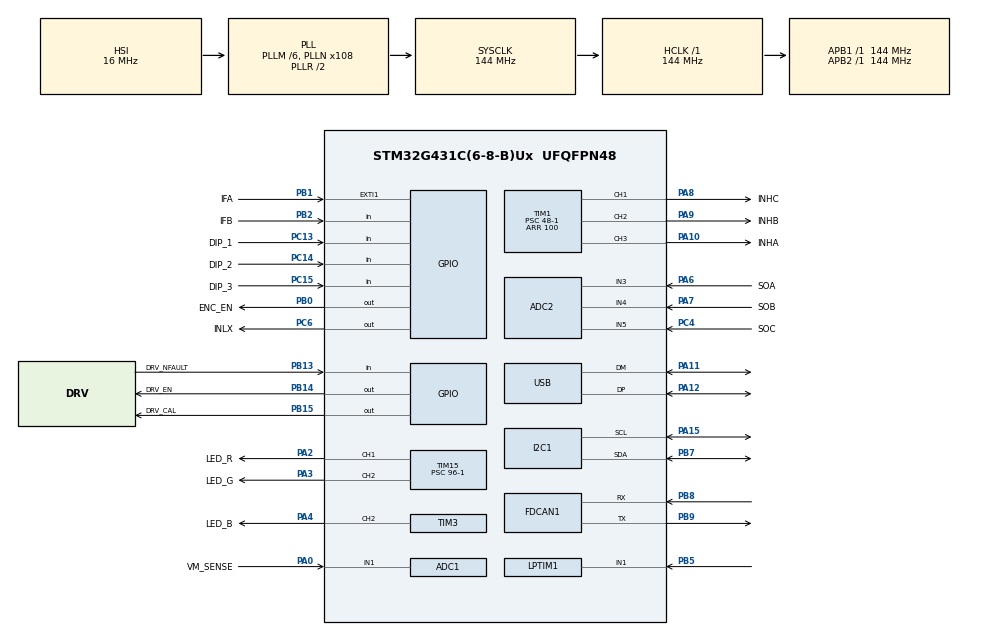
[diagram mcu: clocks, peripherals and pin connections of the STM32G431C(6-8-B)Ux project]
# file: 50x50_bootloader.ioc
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ADC1.Channel-1\#ChannelRegularConversion=ADC_CHANNEL_1
ADC1.Channel-2\#ChannelRegularConversion=ADC_CHANNEL_TEMPSENSOR_ADC1
ADC1.ClockPrescaler=ADC_CLOCK_ASYNC_DIV128
ADC1.ContinuousConvMode=ENABLE
ADC1.DMAContinuousRequests=ENABLE
ADC1.NbrOfConversion=2
ADC1.NbrOfConversionFlag=1
ADC1.OffsetNumber-1\#ChannelRegularConversion=ADC_OFFSET_NONE
ADC1.OffsetNumber-2\#ChannelRegularConversion=ADC_OFFSET_NONE
ADC1.Rank-1\#ChannelRegularConversion=1
ADC1.Rank-2\#ChannelRegularConversion=2
ADC1.SamplingTime-1\#ChannelRegularConversion=ADC_SAMPLETIME_2CYCLES_5
ADC1.SamplingTime-2\#ChannelRegularConversion=ADC_SAMPLETIME_247CYCLES_5
ADC1.master=1
ADC2.Channel-2\#ChannelRegularConversion=ADC_CHANNEL_3
ADC2.Channel-3\#ChannelRegularConversion=ADC_CHANNEL_4
ADC2.Channel-4\#ChannelRegularConversion=ADC_CHANNEL_5
ADC2.ClockPrescaler=ADC_CLOCK_ASYNC_DIV128
ADC2.ContinuousConvMode=ENABLE
ADC2.DMAContinuousRequests=DISABLE
ADC2.EOCSelection=ADC_EOC_SEQ_CONV
ADC2.ExternalTrigConv=ADC_EXTERNALTRIG_T1_TRGO
ADC2.NbrOfConversion=3
ADC2.NbrOfConversionFlag=1
ADC2.OffsetNumber-2\#ChannelRegularConversion=ADC_OFFSET_NONE
ADC2.OffsetNumber-3\#ChannelRegularConversion=ADC_OFFSET_NONE
ADC2.OffsetNumber-4\#ChannelRegularConversion=ADC_OFFSET_NONE
ADC2.Overrun=ADC_OVR_DATA_PRESERVED
ADC2.Rank-2\#ChannelRegularConversion=1
ADC2.Rank-3\#ChannelRegularConversion=2
ADC2.Rank-4\#ChannelRegularConversion=3
ADC2.SamplingTime-2\#ChannelRegularConversion=ADC_SAMPLETIME_6CYCLES_5
ADC2.SamplingTime-3\#ChannelRegularConversion=ADC_SAMPLETIME_6CYCLES_5
ADC2.SamplingTime-4\#ChannelRegularConversion=ADC_SAMPLETIME_6CYCLES_5
Dma.ADC1.0.Direction=DMA_PERIPH_TO_MEMORY
Dma.ADC1.0.EventEnable=DISABLE
Dma.ADC1.0.Instance=DMA1_Channel1
Dma.ADC1.0.MemDataAlignment=DMA_MDATAALIGN_WORD
Dma.ADC1.0.MemInc=DMA_MINC_ENABLE
Dma.ADC1.0.Mode=DMA_CIRCULAR
Dma.ADC1.0.PeriphDataAlignment=DMA_PDATAALIGN_WORD
Dma.ADC1.0.PeriphInc=DMA_PINC_DISABLE
Dma.ADC1.0.Polarity=HAL_DMAMUX_REQ_GEN_RISING
Dma.ADC1.0.Priority=DMA_PRIORITY_LOW
Dma.ADC1.0.RequestNumber=1
Dma.ADC1.0.SignalID=NONE
Dma.ADC1.0.SyncEnable=DISABLE
Dma.ADC1.0.SyncPolarity=HAL_DMAMUX_SYNC_NO_EVENT
Dma.ADC1.0.SyncRequestNumber=1
Dma.ADC1.0.SyncSignalID=NONE
Dma.ADC2.1.Direction=DMA_PERIPH_TO_MEMORY
Dma.ADC2.1.EventEnable=DISABLE
Dma.ADC2.1.Instance=DMA1_Channel2
Dma.ADC2.1.MemDataAlignment=DMA_MDATAALIGN_WORD
Dma.ADC2.1.MemInc=DMA_MINC_ENABLE
Dma.ADC2.1.Mode=DMA_CIRCULAR
Dma.ADC2.1.PeriphDataAlignment=DMA_PDATAALIGN_WORD
Dma.ADC2.1.PeriphInc=DMA_PINC_DISABLE
Dma.ADC2.1.Polarity=HAL_DMAMUX_REQ_GEN_RISING
Dma.ADC2.1.Priority=DMA_PRIORITY_MEDIUM
Dma.ADC2.1.RequestNumber=1
Dma.ADC2.1.SignalID=NONE
Dma.ADC2.1.SyncEnable=DISABLE
Dma.ADC2.1.SyncPolarity=HAL_DMAMUX_SYNC_NO_EVENT
Dma.ADC2.1.SyncRequestNumber=1
Dma.ADC2.1.SyncSignalID=NONE
Dma.Request0=ADC1
Dma.Request1=ADC2
FDCAN1.AutoRetransmission=DISABLE
FDCAN1.CalculateBaudRateNominal=500000
FDCAN1.CalculateTimeBitNominal=2000
FDCAN1.CalculateTimeQuantumNominal=111.11111111111111
FDCAN1.NominalTimeSeg1=15
FDCAN1.TransmitPause=ENABLE
FREERTOS.Tasks01=defaultTask,24,128,StartDefaultTask,Default,NULL,Dynamic,NULL,NULL;statusBlink,8,128,StartStatusBlink,Default,NULL,Dynamic,NULL,NULL;mainStateLoop,40,128,StartMainStateLoop,Default,NULL,Dynamic,NULL,NULL
I2C1.Timing=0x20B0D9FF
Mcu.Family=STM32G4
Mcu.Name=STM32G431C(6-8-B)Ux
Mcu.Package=UFQFPN48
NVIC.DMA1_Channel1_IRQn=true\:5\:0\:false\:false\:true\:true\:false\:true\:true
NVIC.DMA1_Channel2_IRQn=true\:5\:0\:false\:false\:true\:true\:false\:true\:true
NVIC.EXTI1_IRQn=true\:4\:0\:true\:false\:true\:false\:true\:true\:true
NVIC.FDCAN1_IT0_IRQn=true\:5\:0\:false\:false\:true\:true\:true\:true\:true
NVIC.PriorityGroup=NVIC_PRIORITYGROUP_4
NVIC.TIM2_IRQn=true\:15\:0\:false\:false\:true\:false\:false\:true\:true
NVIC.TIM6_DAC_IRQn=true\:5\:0\:true\:false\:true\:true\:true\:true\:true
NVIC.TimeBase=TIM2_IRQn
NVIC.TimeBaseIP=TIM2
NVIC.USB_LP_IRQn=true\:5\:0\:false\:false\:true\:true\:false\:true\:true
PA0.GPIO_Label=VM_SENSE
PA0.Mode=IN1-Single-Ended
PA0.Signal=ADC1_IN1
PA10.GPIO_Label=INHA
PA10.Signal=S_TIM1_CH3
PA11.Mode=Device
PA11.Signal=USB_DM
PA12.Mode=Device
PA12.Signal=USB_DP
PA13.Mode=Trace_Asynchronous_SW
PA13.Signal=SYS_JTMS-SWDIO
PA14.Mode=Trace_Asynchronous_SW
PA14.Signal=SYS_JTCK-SWCLK
PA15.Mode=I2C
PA15.Signal=I2C1_SCL
PA2.GPIO_Label=LED_R
PA2.Signal=S_TIM15_CH1
PA3.GPIO_Label=LED_G
PA3.Signal=S_TIM15_CH2
PA4.GPIO_Label=LED_B
PA4.Signal=S_TIM3_CH2
PA6.GPIO_Label=SOA
PA6.Mode=IN3-Single-Ended
PA6.Signal=ADC2_IN3
PA7.GPIO_Label=SOB
PA7.Mode=IN4-Single-Ended
PA7.Signal=ADC2_IN4
PA8.GPIO_Label=INHC
PA8.Signal=S_TIM1_CH1
PA9.GPIO_Label=INHB
PA9.Signal=S_TIM1_CH2
PB0.GPIO_Label=ENC_EN
PB0.Signal=GPIO_Output
PB1.GPIO_Label=IFA
PB1.Signal=GPXTI1
PB13.GPIO_Label=DRV_NFAULT
PB13.Signal=GPIO_Input
PB14.GPIO_Label=DRV_EN
PB14.Signal=GPIO_Output
PB15.GPIO_Label=DRV_CAL
PB15.Signal=GPIO_Output
PB2.GPIO_Label=IFB
PB2.Signal=GPIO_Input
PB3.Mode=Trace_Asynchronous_SW
PB3.Signal=SYS_JTDO-SWO
PB5.Mode=Counts_external_clock_standalone_1X_occur1
PB5.Signal=LPTIM1_IN1
PB7.Mode=I2C
PB7.Signal=I2C1_SDA
PB8-BOOT0.Mode=FDCAN_Activate
PB8-BOOT0.Signal=FDCAN1_RX
PB9.Mode=FDCAN_Activate
PB9.Signal=FDCAN1_TX
PC13.GPIO_Label=DIP_1
PC13.Signal=GPIO_Input
PC14-OSC32_IN.GPIO_Label=DIP_2
PC14-OSC32_IN.Signal=GPIO_Input
PC15-OSC32_OUT.GPIO_Label=DIP_3
PC15-OSC32_OUT.Signal=GPIO_Input
PC4.GPIO_Label=SOC
PC4.Mode=IN5-Single-Ended
PC4.Signal=ADC2_IN5
PC6.GPIO_Label=INLX
PC6.Signal=GPIO_Output
ProjectManager.HeapSize=0x200
ProjectManager.StackSize=0x400
ProjectManager.TargetToolchain=Makefile
RCC.ADC12Freq_Value=144000000
RCC.AHBFreq_Value=144000000
RCC.APB1Freq_Value=144000000
RCC.APB1TimFreq_Value=144000000
RCC.APB2Freq_Value=144000000
RCC.APB2TimFreq_Value=144000000
RCC.CortexFreq_Value=144000000
RCC.EXTERNAL_CLOCK_VALUE=12288000
RCC.HCLKFreq_Value=144000000
RCC.HSE_VALUE=8000000
RCC.HSI48_VALUE=48000000
RCC.HSI_VALUE=16000000
RCC.LSE_VALUE=32768
RCC.PLLM=RCC_PLLM_DIV6
RCC.PLLN=108
RCC.PLLQ=RCC_PLLQ_DIV6
RCC.SYSCLKFreq_VALUE=144000000
RCC.SYSCLKSource=RCC_SYSCLKSOURCE_PLLCLK
RCC.USBFreq_Value=48000000
RCC.VCOOutputFreq_Value=288000000
SH.S_TIM15_CH1.0=TIM15_CH1,PWM Generation1 CH1
SH.S_TIM15_CH2.0=TIM15_CH2,PWM Generation2 CH2
SH.S_TIM1_CH1.0=TIM1_CH1,PWM Generation1 CH1
SH.S_TIM1_CH2.0=TIM1_CH2,PWM Generation2 CH2
SH.S_TIM1_CH3.0=TIM1_CH3,PWM Generation3 CH3
SH.S_TIM3_CH2.0=TIM3_CH2,PWM Generation2 CH2
TIM1.Channel-PWM\ Generation1\ CH1=TIM_CHANNEL_1
TIM1.Channel-PWM\ Generation2\ CH2=TIM_CHANNEL_2
TIM1.Channel-PWM\ Generation3\ CH3=TIM_CHANNEL_3
TIM1.CounterMode=TIM_COUNTERMODE_CENTERALIGNED1
TIM1.PeriodNoDither=100
TIM1.Prescaler=48-1
TIM1.TIM_MasterOutputTrigger=TIM_TRGO_UPDATE
TIM15.Channel-PWM\ Generation1\ CH1=TIM_CHANNEL_1
TIM15.Channel-PWM\ Generation2\ CH2=TIM_CHANNEL_2
TIM15.OCIdleState_1=TIM_OCIDLESTATE_SET
TIM15.OCIdleState_2=TIM_OCIDLESTATE_SET
TIM15.OCPolarity_1=TIM_OCPOLARITY_LOW
TIM15.OCPolarity_2=TIM_OCPOLARITY_LOW
TIM15.PeriodNoDither=200-1
TIM15.Prescaler=96-1
TIM3.Channel-PWM\ Generation2\ CH2=TIM_CHANNEL_2
TIM3.OCPolarity_2=TIM_OCPOLARITY_LOW
TIM3.PeriodNoDither=200-1
TIM3.Prescaler=96 -1
TIM6.PeriodNoDither=100-1
TIM6.Prescaler=144-1
TIM7.Prescaler=14400-1
USB.Sof_enable=ENABLE
USB_DEVICE.CLASS_NAME_FS=CDC
USB_DEVICE.PRODUCT_STRING_CDC_FS=50x50-Drive
USB_DEVICE.USBD_DEBUG_LEVEL=1
USB_DEVICE.USBD_SELF_POWERED=0
USB_DEVICE.VirtualMode=Cdc
USB_DEVICE.VirtualModeFS=Cdc_FS
VP_ADC1_TempSens_Input.Mode=IN-TempSens
VP_FREERTOS_VS_CMSIS_V2.Mode=CMSIS_V2
VP_SYS_VS_DBSignals.Mode=DisableDeadBatterySignals
VP_SYS_VS_tim2.Mode=TIM2
VP_TIM1_VS_ClockSourceINT.Mode=Internal
VP_TIM6_VS_ClockSourceINT.Mode=Enable_Timer
VP_TIM7_VS_ClockSourceINT.Mode=Enable_Timer
VP_USB_DEVICE_VS_USB_DEVICE_CDC_FS.Mode=CDC_FS
board=custom

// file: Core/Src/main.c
/* USER CODE BEGIN Header */
/**
  ******************************************************************************
  * @file           : main.c
  * @brief          : Main program body
  ******************************************************************************
  * @attention
  *
  * Copyright (c) 2023 STMicroelectronics.
  * All rights reserved.
  *
  * This software is licensed under terms that can be found in the LICENSE file
  * in the root directory of this software component.
  * If no LICENSE file comes with this software, it is provided AS-IS.
  *
  ******************************************************************************
  */
/* USER CODE END Header */
#include "main.h"
#include "cmsis_os.h"
#include "usb_device.h"

/* USER CODE BEGIN Includes */
#include "bootloader.h"
/* USER CODE END Includes */

ADC_HandleTypeDef hadc1;
ADC_HandleTypeDef hadc2;
DMA_HandleTypeDef hdma_adc1;
DMA_HandleTypeDef hdma_adc2;

FDCAN_HandleTypeDef hfdcan1;

I2C_HandleTypeDef hi2c1;

LPTIM_HandleTypeDef hlptim1;

TIM_HandleTypeDef htim1;
TIM_HandleTypeDef htim3;
TIM_HandleTypeDef htim6;
TIM_HandleTypeDef htim7;
TIM_HandleTypeDef htim15;

/* Definitions for defaultTask */
osThreadId_t defaultTaskHandle;
const osThreadAttr_t defaultTask_attributes = {
  .name = "defaultTask",
  .priority = (osPriority_t) osPriorityNormal,
  .stack_size = 128 * 4
};
/* Definitions for statusBlink */
osThreadId_t statusBlinkHandle;
const osThreadAttr_t statusBlink_attributes = {
  .name = "statusBlink",
  .priority = (osPriority_t) osPriorityLow,
  .stack_size = 128 * 4
};
/* Definitions for mainStateLoop */
osThreadId_t mainStateLoopHandle;
const osThreadAttr_t mainStateLoop_attributes = {
  .name = "mainStateLoop",
  .priority = (osPriority_t) osPriorityHigh,
  .stack_size = 128 * 4
};

void SystemClock_Config(void);
static void MX_GPIO_Init(void);
static void MX_DMA_Init(void);
static void MX_FDCAN1_Init(void);
static void MX_ADC1_Init(void);
static void MX_ADC2_Init(void);
static void MX_TIM1_Init(void);
static void MX_I2C1_Init(void);
static void MX_TIM3_Init(void);
static void MX_TIM15_Init(void);
static void MX_TIM6_Init(void);
static void MX_LPTIM1_Init(void);
static void MX_TIM7_Init(void);
void StartDefaultTask(void *argument);
void StartStatusBlink(void *argument);
void StartMainStateLoop(void *argument);

int main(void)
{
  /* USER CODE BEGIN 1 */
  // Hello world 2
  /* USER CODE END 1 */

  /* MCU Configuration--------------------------------------------------------*/

  /* Reset of all peripherals, Initializes the Flash interface and the Systick. */
  HAL_Init();

  /* Configure the system clock */
  SystemClock_Config();

  /* Initialize all configured peripherals */
  MX_GPIO_Init();
  MX_DMA_Init();
  MX_FDCAN1_Init();
  MX_ADC1_Init();
  MX_ADC2_Init();
  MX_TIM1_Init();
  MX_I2C1_Init();
  MX_USB_Device_Init();
  MX_TIM3_Init();
  MX_TIM15_Init();
  MX_TIM6_Init();
  MX_LPTIM1_Init();
  MX_TIM7_Init();
  /* USER CODE BEGIN 2 */
  bootloader_init();

  HAL_GPIO_WritePin(LED_R_GPIO_Port, LED_R_Pin, 1);
  HAL_GPIO_WritePin(LED_G_GPIO_Port, LED_G_Pin, 1);
  HAL_GPIO_WritePin(LED_B_GPIO_Port, LED_B_Pin, 1);
  /* USER CODE END 2 */

  /* Init scheduler */
  osKernelInitialize();

  /* Create the thread(s) */
  /* creation of defaultTask */
  defaultTaskHandle = osThreadNew(StartDefaultTask, NULL, &defaultTask_attributes);

  /* creation of statusBlink */
  statusBlinkHandle = osThreadNew(StartStatusBlink, NULL, &statusBlink_attributes);

  /* creation of mainStateLoop */
  mainStateLoopHandle = osThreadNew(StartMainStateLoop, NULL, &mainStateLoop_attributes);

  /* Start scheduler */
  osKernelStart();

  /* We should never get here as control is now taken by the scheduler */
  /* Infinite loop */
  while (1)
  {

    /* USER CODE BEGIN 3 */
    bootloader_loop();
  }
  /* USER CODE END 3 */
}

void SystemClock_Config(void)
{
  RCC_OscInitTypeDef RCC_OscInitStruct = {0};
  RCC_ClkInitTypeDef RCC_ClkInitStruct = {0};

  /** Configure the main internal regulator output voltage
  */
  HAL_PWREx_ControlVoltageScaling(PWR_REGULATOR_VOLTAGE_SCALE1);

  /** Initializes the RCC Oscillators according to the specified parameters
  * in the RCC_OscInitTypeDef structure.
  */
  RCC_OscInitStruct.OscillatorType = RCC_OSCILLATORTYPE_HSI;
  RCC_OscInitStruct.HSIState = RCC_HSI_ON;
  RCC_OscInitStruct.HSICalibrationValue = RCC_HSICALIBRATION_DEFAULT;
  RCC_OscInitStruct.PLL.PLLState = RCC_PLL_ON;
  RCC_OscInitStruct.PLL.PLLSource = RCC_PLLSOURCE_HSI;
  RCC_OscInitStruct.PLL.PLLM = RCC_PLLM_DIV6;
  RCC_OscInitStruct.PLL.PLLN = 108;
  RCC_OscInitStruct.PLL.PLLP = RCC_PLLP_DIV2;
  RCC_OscInitStruct.PLL.PLLQ = RCC_PLLQ_DIV6;
  RCC_OscInitStruct.PLL.PLLR = RCC_PLLR_DIV2;
  if (HAL_RCC_OscConfig(&RCC_OscInitStruct) != HAL_OK)
  {
    Error_Handler();
  }

  /** Initializes the CPU, AHB and APB buses clocks
  */
  RCC_ClkInitStruct.ClockType = RCC_CLOCKTYPE_HCLK|RCC_CLOCKTYPE_SYSCLK
                              |RCC_CLOCKTYPE_PCLK1|RCC_CLOCKTYPE_PCLK2;
  RCC_ClkInitStruct.SYSCLKSource = RCC_SYSCLKSOURCE_PLLCLK;
  RCC_ClkInitStruct.AHBCLKDivider = RCC_SYSCLK_DIV1;
  RCC_ClkInitStruct.APB1CLKDivider = RCC_HCLK_DIV1;
  RCC_ClkInitStruct.APB2CLKDivider = RCC_HCLK_DIV1;

  if (HAL_RCC_ClockConfig(&RCC_ClkInitStruct, FLASH_LATENCY_4) != HAL_OK)
  {
    Error_Handler();
  }
}

static void MX_ADC1_Init(void)
{

  ADC_MultiModeTypeDef multimode = {0};
  ADC_ChannelConfTypeDef sConfig = {0};

  /** Common config
  */
  hadc1.Instance = ADC1;
  hadc1.Init.ClockPrescaler = ADC_CLOCK_ASYNC_DIV128;
  hadc1.Init.Resolution = ADC_RESOLUTION_12B;
  hadc1.Init.DataAlign = ADC_DATAALIGN_RIGHT;
  hadc1.Init.GainCompensation = 0;
  hadc1.Init.ScanConvMode = ADC_SCAN_ENABLE;
  hadc1.Init.EOCSelection = ADC_EOC_SINGLE_CONV;
  hadc1.Init.LowPowerAutoWait = DISABLE;
  hadc1.Init.ContinuousConvMode = ENABLE;
  hadc1.Init.NbrOfConversion = 2;
  hadc1.Init.DiscontinuousConvMode = DISABLE;
  hadc1.Init.ExternalTrigConv = ADC_SOFTWARE_START;
  hadc1.Init.ExternalTrigConvEdge = ADC_EXTERNALTRIGCONVEDGE_NONE;
  hadc1.Init.DMAContinuousRequests = ENABLE;
  hadc1.Init.Overrun = ADC_OVR_DATA_PRESERVED;
  hadc1.Init.OversamplingMode = DISABLE;
  if (HAL_ADC_Init(&hadc1) != HAL_OK)
  {
    Error_Handler();
  }

  /** Configure the ADC multi-mode
  */
  multimode.Mode = ADC_MODE_INDEPENDENT;
  if (HAL_ADCEx_MultiModeConfigChannel(&hadc1, &multimode) != HAL_OK)
  {
    Error_Handler();
  }

  /** Configure Regular Channel
  */
  sConfig.Channel = ADC_CHANNEL_1;
  sConfig.Rank = ADC_REGULAR_RANK_1;
  sConfig.SamplingTime = ADC_SAMPLETIME_2CYCLES_5;
  sConfig.SingleDiff = ADC_SINGLE_ENDED;
  sConfig.OffsetNumber = ADC_OFFSET_NONE;
  sConfig.Offset = 0;
  if (HAL_ADC_ConfigChannel(&hadc1, &sConfig) != HAL_OK)
  {
    Error_Handler();
  }

  /** Configure Regular Channel
  */
  sConfig.Channel = ADC_CHANNEL_TEMPSENSOR_ADC1;
  sConfig.Rank = ADC_REGULAR_RANK_2;
  sConfig.SamplingTime = ADC_SAMPLETIME_247CYCLES_5;
  if (HAL_ADC_ConfigChannel(&hadc1, &sConfig) != HAL_OK)
  {
    Error_Handler();
  }

}

static void MX_ADC2_Init(void)
{

  ADC_ChannelConfTypeDef sConfig = {0};

  /** Common config
  */
  hadc2.Instance = ADC2;
  hadc2.Init.ClockPrescaler = ADC_CLOCK_ASYNC_DIV128;
  hadc2.Init.Resolution = ADC_RESOLUTION_12B;
  hadc2.Init.DataAlign = ADC_DATAALIGN_RIGHT;
  hadc2.Init.GainCompensation = 0;
  hadc2.Init.ScanConvMode = ADC_SCAN_ENABLE;
  hadc2.Init.EOCSelection = ADC_EOC_SEQ_CONV;
  hadc2.Init.LowPowerAutoWait = DISABLE;
  hadc2.Init.ContinuousConvMode = ENABLE;
  hadc2.Init.NbrOfConversion = 3;
  hadc2.Init.DiscontinuousConvMode = DISABLE;
  hadc2.Init.ExternalTrigConv = ADC_EXTERNALTRIG_T1_TRGO;
  hadc2.Init.ExternalTrigConvEdge = ADC_EXTERNALTRIGCONVEDGE_RISING;
  hadc2.Init.DMAContinuousRequests = DISABLE;
  hadc2.Init.Overrun = ADC_OVR_DATA_PRESERVED;
  hadc2.Init.OversamplingMode = DISABLE;
  if (HAL_ADC_Init(&hadc2) != HAL_OK)
  {
    Error_Handler();
  }

  /** Configure Regular Channel
  */
  sConfig.Channel = ADC_CHANNEL_3;
  sConfig.Rank = ADC_REGULAR_RANK_1;
  sConfig.SamplingTime = ADC_SAMPLETIME_6CYCLES_5;
  sConfig.SingleDiff = ADC_SINGLE_ENDED;
  sConfig.OffsetNumber = ADC_OFFSET_NONE;
  sConfig.Offset = 0;
  if (HAL_ADC_ConfigChannel(&hadc2, &sConfig) != HAL_OK)
  {
    Error_Handler();
  }

  /** Configure Regular Channel
  */
  sConfig.Channel = ADC_CHANNEL_4;
  sConfig.Rank = ADC_REGULAR_RANK_2;
  if (HAL_ADC_ConfigChannel(&hadc2, &sConfig) != HAL_OK)
  {
    Error_Handler();
  }

  /** Configure Regular Channel
  */
  sConfig.Channel = ADC_CHANNEL_5;
  sConfig.Rank = ADC_REGULAR_RANK_3;
  if (HAL_ADC_ConfigChannel(&hadc2, &sConfig) != HAL_OK)
  {
    Error_Handler();
  }

}

static void MX_FDCAN1_Init(void)
{

  hfdcan1.Instance = FDCAN1;
  hfdcan1.Init.ClockDivider = FDCAN_CLOCK_DIV1;
  hfdcan1.Init.FrameFormat = FDCAN_FRAME_CLASSIC;
  hfdcan1.Init.Mode = FDCAN_MODE_NORMAL;
  hfdcan1.Init.AutoRetransmission = DISABLE;
  hfdcan1.Init.TransmitPause = ENABLE;
  hfdcan1.Init.ProtocolException = DISABLE;
  hfdcan1.Init.NominalPrescaler = 16;
  hfdcan1.Init.NominalSyncJumpWidth = 1;
  hfdcan1.Init.NominalTimeSeg1 = 15;
  hfdcan1.Init.NominalTimeSeg2 = 2;
  hfdcan1.Init.DataPrescaler = 1;
  hfdcan1.Init.DataSyncJumpWidth = 1;
  hfdcan1.Init.DataTimeSeg1 = 1;
  hfdcan1.Init.DataTimeSeg2 = 1;
  hfdcan1.Init.StdFiltersNbr = 0;
  hfdcan1.Init.ExtFiltersNbr = 0;
  hfdcan1.Init.TxFifoQueueMode = FDCAN_TX_FIFO_OPERATION;
  if (HAL_FDCAN_Init(&hfdcan1) != HAL_OK)
  {
    Error_Handler();
  }

}

static void MX_I2C1_Init(void)
{

  hi2c1.Instance = I2C1;
  hi2c1.Init.Timing = 0x20B0D9FF;
  hi2c1.Init.OwnAddress1 = 0;
  hi2c1.Init.AddressingMode = I2C_ADDRESSINGMODE_7BIT;
  hi2c1.Init.DualAddressMode = I2C_DUALADDRESS_DISABLE;
  hi2c1.Init.OwnAddress2 = 0;
  hi2c1.Init.OwnAddress2Masks = I2C_OA2_NOMASK;
  hi2c1.Init.GeneralCallMode = I2C_GENERALCALL_DISABLE;
  hi2c1.Init.NoStretchMode = I2C_NOSTRETCH_DISABLE;
  if (HAL_I2C_Init(&hi2c1) != HAL_OK)
  {
    Error_Handler();
  }

  /** Configure Analogue filter
  */
  if (HAL_I2CEx_ConfigAnalogFilter(&hi2c1, I2C_ANALOGFILTER_ENABLE) != HAL_OK)
  {
    Error_Handler();
  }

  /** Configure Digital filter
  */
  if (HAL_I2CEx_ConfigDigitalFilter(&hi2c1, 0) != HAL_OK)
  {
    Error_Handler();
  }

}

static void MX_LPTIM1_Init(void)
{

  hlptim1.Instance = LPTIM1;
  hlptim1.Init.Clock.Source = LPTIM_CLOCKSOURCE_ULPTIM;
  hlptim1.Init.Clock.Prescaler = LPTIM_PRESCALER_DIV1;
  hlptim1.Init.UltraLowPowerClock.Polarity = LPTIM_CLOCKPOLARITY_RISING;
  hlptim1.Init.UltraLowPowerClock.SampleTime = LPTIM_CLOCKSAMPLETIME_DIRECTTRANSITION;
  hlptim1.Init.Trigger.Source = LPTIM_TRIGSOURCE_SOFTWARE;
  hlptim1.Init.OutputPolarity = LPTIM_OUTPUTPOLARITY_HIGH;
  hlptim1.Init.UpdateMode = LPTIM_UPDATE_IMMEDIATE;
  hlptim1.Init.CounterSource = LPTIM_COUNTERSOURCE_EXTERNAL;
  hlptim1.Init.Input1Source = LPTIM_INPUT1SOURCE_GPIO;
  hlptim1.Init.Input2Source = LPTIM_INPUT2SOURCE_GPIO;
  if (HAL_LPTIM_Init(&hlptim1) != HAL_OK)
  {
    Error_Handler();
  }

}

static void MX_TIM1_Init(void)
{

  TIM_ClockConfigTypeDef sClockSourceConfig = {0};
  TIM_MasterConfigTypeDef sMasterConfig = {0};
  TIM_OC_InitTypeDef sConfigOC = {0};
  TIM_BreakDeadTimeConfigTypeDef sBreakDeadTimeConfig = {0};

  htim1.Instance = TIM1;
  htim1.Init.Prescaler = 48-1;
  htim1.Init.CounterMode = TIM_COUNTERMODE_CENTERALIGNED1;
  htim1.Init.Period = 100;
  htim1.Init.ClockDivision = TIM_CLOCKDIVISION_DIV1;
  htim1.Init.RepetitionCounter = 0;
  htim1.Init.AutoReloadPreload = TIM_AUTORELOAD_PRELOAD_DISABLE;
  if (HAL_TIM_Base_Init(&htim1) != HAL_OK)
  {
    Error_Handler();
  }
  sClockSourceConfig.ClockSource = TIM_CLOCKSOURCE_INTERNAL;
  if (HAL_TIM_ConfigClockSource(&htim1, &sClockSourceConfig) != HAL_OK)
  {
    Error_Handler();
  }
  if (HAL_TIM_PWM_Init(&htim1) != HAL_OK)
  {
    Error_Handler();
  }
  sMasterConfig.MasterOutputTrigger = TIM_TRGO_UPDATE;
  sMasterConfig.MasterOutputTrigger2 = TIM_TRGO2_RESET;
  sMasterConfig.MasterSlaveMode = TIM_MASTERSLAVEMODE_DISABLE;
  if (HAL_TIMEx_MasterConfigSynchronization(&htim1, &sMasterConfig) != HAL_OK)
  {
    Error_Handler();
  }
  sConfigOC.OCMode = TIM_OCMODE_PWM1;
  sConfigOC.Pulse = 0;
  sConfigOC.OCPolarity = TIM_OCPOLARITY_HIGH;
  sConfigOC.OCNPolarity = TIM_OCNPOLARITY_HIGH;
  sConfigOC.OCFastMode = TIM_OCFAST_DISABLE;
  sConfigOC.OCIdleState = TIM_OCIDLESTATE_RESET;
  sConfigOC.OCNIdleState = TIM_OCNIDLESTATE_RESET;
  if (HAL_TIM_PWM_ConfigChannel(&htim1, &sConfigOC, TIM_CHANNEL_1) != HAL_OK)
  {
    Error_Handler();
  }
  if (HAL_TIM_PWM_ConfigChannel(&htim1, &sConfigOC, TIM_CHANNEL_2) != HAL_OK)
  {
    Error_Handler();
  }
  if (HAL_TIM_PWM_ConfigChannel(&htim1, &sConfigOC, TIM_CHANNEL_3) != HAL_OK)
  {
    Error_Handler();
  }
  sBreakDeadTimeConfig.OffStateRunMode = TIM_OSSR_DISABLE;
  sBreakDeadTimeConfig.OffStateIDLEMode = TIM_OSSI_DISABLE;
  sBreakDeadTimeConfig.LockLevel = TIM_LOCKLEVEL_OFF;
  sBreakDeadTimeConfig.DeadTime = 0;
  sBreakDeadTimeConfig.BreakState = TIM_BREAK_DISABLE;
  sBreakDeadTimeConfig.BreakPolarity = TIM_BREAKPOLARITY_HIGH;
  sBreakDeadTimeConfig.BreakFilter = 0;
  sBreakDeadTimeConfig.BreakAFMode = TIM_BREAK_AFMODE_INPUT;
  sBreakDeadTimeConfig.Break2State = TIM_BREAK2_DISABLE;
  sBreakDeadTimeConfig.Break2Polarity = TIM_BREAK2POLARITY_HIGH;
  sBreakDeadTimeConfig.Break2Filter = 0;
  sBreakDeadTimeConfig.Break2AFMode = TIM_BREAK_AFMODE_INPUT;
  sBreakDeadTimeConfig.AutomaticOutput = TIM_AUTOMATICOUTPUT_DISABLE;
  if (HAL_TIMEx_ConfigBreakDeadTime(&htim1, &sBreakDeadTimeConfig) != HAL_OK)
  {
    Error_Handler();
  }
  HAL_TIM_MspPostInit(&htim1);

}

static void MX_TIM3_Init(void)
{

  TIM_MasterConfigTypeDef sMasterConfig = {0};
  TIM_OC_InitTypeDef sConfigOC = {0};

  htim3.Instance = TIM3;
  htim3.Init.Prescaler = 96 -1;
  htim3.Init.CounterMode = TIM_COUNTERMODE_UP;
  htim3.Init.Period = 199;
  htim3.Init.ClockDivision = TIM_CLOCKDIVISION_DIV1;
  htim3.Init.AutoReloadPreload = TIM_AUTORELOAD_PRELOAD_DISABLE;
  if (HAL_TIM_PWM_Init(&htim3) != HAL_OK)
  {
    Error_Handler();
  }
  sMasterConfig.MasterOutputTrigger = TIM_TRGO_RESET;
  sMasterConfig.MasterSlaveMode = TIM_MASTERSLAVEMODE_DISABLE;
  if (HAL_TIMEx_MasterConfigSynchronization(&htim3, &sMasterConfig) != HAL_OK)
  {
    Error_Handler();
  }
  sConfigOC.OCMode = TIM_OCMODE_PWM1;
  sConfigOC.Pulse = 0;
  sConfigOC.OCPolarity = TIM_OCPOLARITY_LOW;
  sConfigOC.OCFastMode = TIM_OCFAST_DISABLE;
  if (HAL_TIM_PWM_ConfigChannel(&htim3, &sConfigOC, TIM_CHANNEL_2) != HAL_OK)
  {
    Error_Handler();
  }
  HAL_TIM_MspPostInit(&htim3);

}

static void MX_TIM6_Init(void)
{

  TIM_MasterConfigTypeDef sMasterConfig = {0};

  htim6.Instance = TIM6;
  htim6.Init.Prescaler = 144-1;
  htim6.Init.CounterMode = TIM_COUNTERMODE_UP;
  htim6.Init.Period = 99;
  htim6.Init.AutoReloadPreload = TIM_AUTORELOAD_PRELOAD_DISABLE;
  if (HAL_TIM_Base_Init(&htim6) != HAL_OK)
  {
    Error_Handler();
  }
  sMasterConfig.MasterOutputTrigger = TIM_TRGO_RESET;
  sMasterConfig.MasterSlaveMode = TIM_MASTERSLAVEMODE_DISABLE;
  if (HAL_TIMEx_MasterConfigSynchronization(&htim6, &sMasterConfig) != HAL_OK)
  {
    Error_Handler();
  }

}

static void MX_TIM7_Init(void)
{

  TIM_MasterConfigTypeDef sMasterConfig = {0};

  htim7.Instance = TIM7;
  htim7.Init.Prescaler = 14400-1;
  htim7.Init.CounterMode = TIM_COUNTERMODE_UP;
  htim7.Init.Period = 65535;
  htim7.Init.AutoReloadPreload = TIM_AUTORELOAD_PRELOAD_DISABLE;
  if (HAL_TIM_Base_Init(&htim7) != HAL_OK)
  {
    Error_Handler();
  }
  sMasterConfig.MasterOutputTrigger = TIM_TRGO_RESET;
  sMasterConfig.MasterSlaveMode = TIM_MASTERSLAVEMODE_DISABLE;
  if (HAL_TIMEx_MasterConfigSynchronization(&htim7, &sMasterConfig) != HAL_OK)
  {
    Error_Handler();
  }

}

static void MX_TIM15_Init(void)
{

  TIM_MasterConfigTypeDef sMasterConfig = {0};
  TIM_OC_InitTypeDef sConfigOC = {0};
  TIM_BreakDeadTimeConfigTypeDef sBreakDeadTimeConfig = {0};

  htim15.Instance = TIM15;
  htim15.Init.Prescaler = 96-1;
  htim15.Init.CounterMode = TIM_COUNTERMODE_UP;
  htim15.Init.Period = 199;
  htim15.Init.ClockDivision = TIM_CLOCKDIVISION_DIV1;
  htim15.Init.RepetitionCounter = 0;
  htim15.Init.AutoReloadPreload = TIM_AUTORELOAD_PRELOAD_DISABLE;
  if (HAL_TIM_PWM_Init(&htim15) != HAL_OK)
  {
    Error_Handler();
  }
  sMasterConfig.MasterOutputTrigger = TIM_TRGO_RESET;
  sMasterConfig.MasterSlaveMode = TIM_MASTERSLAVEMODE_DISABLE;
  if (HAL_TIMEx_MasterConfigSynchronization(&htim15, &sMasterConfig) != HAL_OK)
  {
    Error_Handler();
  }
  sConfigOC.OCMode = TIM_OCMODE_PWM1;
  sConfigOC.Pulse = 0;
  sConfigOC.OCPolarity = TIM_OCPOLARITY_LOW;
  sConfigOC.OCNPolarity = TIM_OCNPOLARITY_HIGH;
  sConfigOC.OCFastMode = TIM_OCFAST_DISABLE;
  sConfigOC.OCIdleState = TIM_OCIDLESTATE_SET;
  sConfigOC.OCNIdleState = TIM_OCNIDLESTATE_RESET;
  if (HAL_TIM_PWM_ConfigChannel(&htim15, &sConfigOC, TIM_CHANNEL_1) != HAL_OK)
  {
    Error_Handler();
  }
  if (HAL_TIM_PWM_ConfigChannel(&htim15, &sConfigOC, TIM_CHANNEL_2) != HAL_OK)
  {
    Error_Handler();
  }
  sBreakDeadTimeConfig.OffStateRunMode = TIM_OSSR_DISABLE;
  sBreakDeadTimeConfig.OffStateIDLEMode = TIM_OSSI_DISABLE;
  sBreakDeadTimeConfig.LockLevel = TIM_LOCKLEVEL_OFF;
  sBreakDeadTimeConfig.DeadTime = 0;
  sBreakDeadTimeConfig.BreakState = TIM_BREAK_DISABLE;
  sBreakDeadTimeConfig.BreakPolarity = TIM_BREAKPOLARITY_HIGH;
  sBreakDeadTimeConfig.BreakFilter = 0;
  sBreakDeadTimeConfig.AutomaticOutput = TIM_AUTOMATICOUTPUT_DISABLE;
  if (HAL_TIMEx_ConfigBreakDeadTime(&htim15, &sBreakDeadTimeConfig) != HAL_OK)
  {
    Error_Handler();
  }
  HAL_TIM_MspPostInit(&htim15);

}

static void MX_DMA_Init(void)
{

  /* DMA controller clock enable */
  __HAL_RCC_DMAMUX1_CLK_ENABLE();
  __HAL_RCC_DMA1_CLK_ENABLE();

  /* DMA interrupt init */
  /* DMA1_Channel1_IRQn interrupt configuration */
  HAL_NVIC_SetPriority(DMA1_Channel1_IRQn, 5, 0);
  HAL_NVIC_EnableIRQ(DMA1_Channel1_IRQn);
  /* DMA1_Channel2_IRQn interrupt configuration */
  HAL_NVIC_SetPriority(DMA1_Channel2_IRQn, 5, 0);
  HAL_NVIC_EnableIRQ(DMA1_Channel2_IRQn);

}

static void MX_GPIO_Init(void)
{
  GPIO_InitTypeDef GPIO_InitStruct = {0};

  /* GPIO Ports Clock Enable */
  __HAL_RCC_GPIOC_CLK_ENABLE();
  __HAL_RCC_GPIOA_CLK_ENABLE();
  __HAL_RCC_GPIOB_CLK_ENABLE();

  /*Configure GPIO pin Output Level */
  HAL_GPIO_WritePin(GPIOB, ENC_EN_Pin|DRV_EN_Pin|DRV_CAL_Pin, GPIO_PIN_RESET);

  /*Configure GPIO pin Output Level */
  HAL_GPIO_WritePin(INLX_GPIO_Port, INLX_Pin, GPIO_PIN_RESET);

  /*Configure GPIO pins : DIP_1_Pin DIP_2_Pin DIP_3_Pin */
  GPIO_InitStruct.Pin = DIP_1_Pin|DIP_2_Pin|DIP_3_Pin;
  GPIO_InitStruct.Mode = GPIO_MODE_INPUT;
  GPIO_InitStruct.Pull = GPIO_NOPULL;
  HAL_GPIO_Init(GPIOC, &GPIO_InitStruct);

  /*Configure GPIO pins : ENC_EN_Pin DRV_EN_Pin DRV_CAL_Pin */
  GPIO_InitStruct.Pin = ENC_EN_Pin|DRV_EN_Pin|DRV_CAL_Pin;
  GPIO_InitStruct.Mode = GPIO_MODE_OUTPUT_PP;
  GPIO_InitStruct.Pull = GPIO_NOPULL;
  GPIO_InitStruct.Speed = GPIO_SPEED_FREQ_LOW;
  HAL_GPIO_Init(GPIOB, &GPIO_InitStruct);

  /*Configure GPIO pin : IFA_Pin */
  GPIO_InitStruct.Pin = IFA_Pin;
  GPIO_InitStruct.Mode = GPIO_MODE_IT_RISING;
  GPIO_InitStruct.Pull = GPIO_NOPULL;
  HAL_GPIO_Init(IFA_GPIO_Port, &GPIO_InitStruct);

  /*Configure GPIO pins : IFB_Pin DRV_NFAULT_Pin */
  GPIO_InitStruct.Pin = IFB_Pin|DRV_NFAULT_Pin;
  GPIO_InitStruct.Mode = GPIO_MODE_INPUT;
  GPIO_InitStruct.Pull = GPIO_NOPULL;
  HAL_GPIO_Init(GPIOB, &GPIO_InitStruct);

  /*Configure GPIO pin : INLX_Pin */
  GPIO_InitStruct.Pin = INLX_Pin;
  GPIO_InitStruct.Mode = GPIO_MODE_OUTPUT_PP;
  GPIO_InitStruct.Pull = GPIO_NOPULL;
  GPIO_InitStruct.Speed = GPIO_SPEED_FREQ_LOW;
  HAL_GPIO_Init(INLX_GPIO_Port, &GPIO_InitStruct);

  /* EXTI interrupt init*/
  HAL_NVIC_SetPriority(EXTI1_IRQn, 4, 0);
  HAL_NVIC_EnableIRQ(EXTI1_IRQn);

}

void StartDefaultTask(void *argument)
{
  for(;;)
  {
    osDelay(1);
  }
}

void StartStatusBlink(void *argument)
{
  for(;;)
  {
    osDelay(1);
  }
}

void StartMainStateLoop(void *argument)
{
  for(;;)
  {
    osDelay(1);
  }
}

void HAL_TIM_PeriodElapsedCallback(TIM_HandleTypeDef *htim)
{
  if (htim->Instance == TIM2) {
    HAL_IncTick();
  }
}

void Error_Handler(void)
{
  __disable_irq();
  while (1)
  {
  }
}
